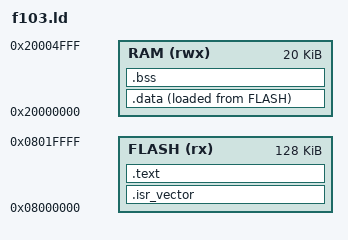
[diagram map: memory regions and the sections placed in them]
/* STM32F103 兼容片链接脚本
 * Flash 128KB（兼容片常见容量，正品 C8T6 为 64KB）
 * RAM 20KB
 */
ENTRY(Reset_Handler)

MEMORY
{
    FLASH (rx)  : ORIGIN = 0x08000000, LENGTH = 128K
    RAM   (rwx) : ORIGIN = 0x20000000, LENGTH = 20K
}

_estack = ORIGIN(RAM) + LENGTH(RAM);

SECTIONS
{
    .isr_vector :
    {
        KEEP(*(.isr_vector))
    } > FLASH

    .text :
    {
        *(.text*)
        *(.rodata*)
        . = ALIGN(4);
    } > FLASH

    _sidata = LOADADDR(.data);

    .data :
    {
        . = ALIGN(4);
        _sdata = .;
        *(.data*)
        . = ALIGN(4);
        _edata = .;
    } > RAM AT> FLASH

    .bss :
    {
        . = ALIGN(4);
        _sbss = .;
        *(.bss*)
        *(COMMON)
        . = ALIGN(4);
        _ebss = .;
    } > RAM

    /DISCARD/ : { *(.ARM.attributes) }
}
